# STM32N645 register map
File version: 1.0
CPU: CM55 r0p1, little endian, no MPU, FPU, vendor SysTick, 8 interrupt priority bits
Registers are 32-bit, read-write, reset 0x0 unless marked. A register's access mark holds for its fields unless they carry their own. Offsets are from the block's base; [hi:lo] are bit positions; {n}, {i} and the like mark numbered series.

## PSSI — Parallel synchronous slave interface
Base 0x48026400
Same registers: PSSI_S 0x58026400
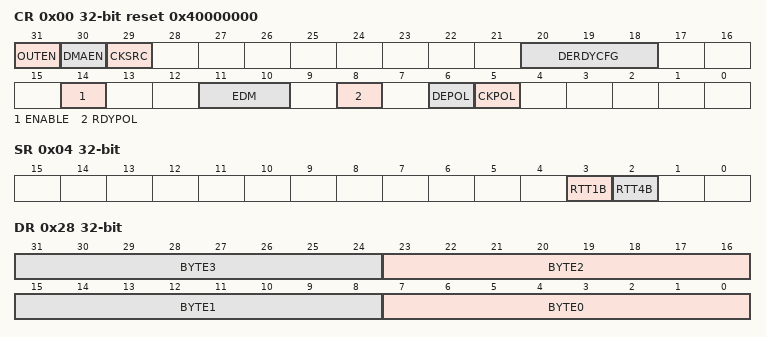
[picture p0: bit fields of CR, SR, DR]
0x00 CR reset 0x40000000 — PSSI control register
  [31] OUTEN — Data direction selection bit
    0=ReceiveMode (Data is input synchronously with PSSI_PDCK); 1=TransmitMode (Data is output synchronously with PSSI_PDCK)
  [30] DMAEN — DMA enable bit
    0=Disabled (DMA transfers are disabled. The user application can directly access the PSSI_DR register when DMA transfers are disabled.); 1=Enabled (DMA transfers are enabled (default configuration). A DMA channel in the general-purpose DMA controller must be configured to perform transfers from/to PSSI_DR)
  [29] CKSRC — Clock source
  [20:18] DERDYCFG — Data enable and ready configuration
    0=Disabled (PSSI_DE and PSSI_RDY both disabled); 1=Rdy (Only PSSI_RDY enabled); 2=De (Only PSSI_DE enabled); 3=RdyDeAlt (Both PSSI_RDY and PSSI_DE alternate functions enabled); 4=RdyDe (Both PSSI_RDY and PSSI_DE features enabled - bidirectional on PSSI_RDY pin); 5=RdyRemapped (Only PSSI_RDY function enabled, but mapped to PSSI_DE pin); 6=DeRemapped (Only PSSI_DE function enabled, but mapped to PSSI_RDY pin); 7=RdyDeBidi (Both PSSI_RDY and PSSI_DE features enabled - bidirectional on PSSI_DE pin)
  [14] ENABLE — PSSI enable
    0=Disabled (PSSI disabled); 1=Enabled (PSSI enabled)
  [11:10] EDM — Extended data mode
    0=BitWidth8 (Interface captures 8-bit data on every parallel data clock); 3=BitWidth16 (The interface captures 16-bit data on every parallel data clock)
  [8] RDYPOL — Ready (PSSI_RDY) polarity
    0=ActiveLow (PSSI_RDY active low (0 indicates that the receiver is ready to receive)); 1=ActiveHigh (PSSI_RDY active high (1 indicates that the receiver is ready to receive))
  [6] DEPOL — Data enable (PSSI_DE) polarity
    0=ActiveLow (PSSI_DE active low (0 indicates that data is valid)); 1=ActiveHigh (PSSI_DE active high (1 indicates that data is valid))
  [5] CKPOL — Parallel data clock polarity
    0=Falling edge active for inputs or rising edge active for outputs; 1=Rising edge active for inputs or falling edge active for outputs
0x04 SR ro — PSSI status register
  [3] RTT1B — FIFO is ready to transfer one byte
    0=NotReady (FIFO is not ready for a 1-byte transfer); 1=Ready (FIFO is ready for a one byte (32-bit) transfer. In receive mode, this means that at least one valid data byte is in the FIFO. In transmit mode, this means that there is at least one byte free in the FIFO)
  [2] RTT4B — FIFO is ready to transfer four bytes
    0=NotReady (FIFO is not ready for a four-byte transfer); 1=Ready (FIFO is ready for a four-byte (32-bit) transfer. In receive mode, this means that at least four valid data bytes are in the FIFO. In transmit mode, this means that there are at least four bytes free in the FIFO)
0x08 RIS ro — PSSI raw interrupt status register
  [1] OVR_RIS — Data buffer overrun/underrun raw interrupt status
    0=Cleared (No overrun/underrun occurred); 1=Occurred (An overrun/underrun occurred: overrun in receive mode, underrun in transmit mode. This bit is cleared by writing a 1 to the OVR_ISC bit in PSSI_ICR)
0x0C IER — PSSI interrupt enable register
  [1] OVR_IE — Data buffer overrun/underrun interrupt enable
    0=Disabled (No interrupt generation); 1=Enabled (An interrupt is generated if either an overrun or an underrun error occurred)
0x10 MIS ro — PSSI masked interrupt status register
  [1] OVR_MIS — Data buffer overrun/underrun masked interrupt status
    0=Disabled (No interrupt is generated when an overrun/underrun error occurs); 1=Enabled (An interrupt is generated if there is either an overrun or an underrun error and the OVR_IE bit is set in PSSI_IER)
0x14 ICR wo — PSSI interrupt clear register
  [1] OVR_ISC — Data buffer overrun/underrun interrupt status clear
    1=Clear (Writing this bit to 1 clears the OVR_RIS bit in PSSI_RIS)
0x28 DR — PSSI data register
  [8n+7:8n] BYTE{n} (n=0..3) — Data byte {n}
